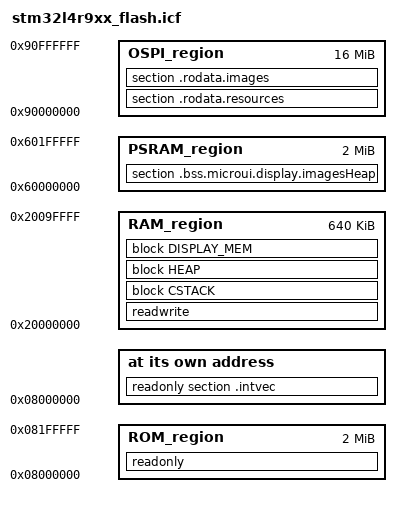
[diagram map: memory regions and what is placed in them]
/*
 * Copyright 2019-2022 MicroEJ Corp. All rights reserved.
 * Use of this source code is governed by a BSD-style license that can be found with this software.
 */

/*-Specials-*/
define symbol __ICFEDIT_intvec_start__ = 0x08000000;
/*-Memory Regions-*/
define symbol __ICFEDIT_region_ROM_start__    = 0x08000000;
define symbol __ICFEDIT_region_ROM_end__      = 0x081FFFFF;
define symbol __ICFEDIT_region_RAM_start__    = 0x20000000;
define symbol __ICFEDIT_region_RAM_end__      = 0x2009FFFF;
define symbol __ICFEDIT_region_PSRAM_start__  = 0x60000000;
define symbol __ICFEDIT_region_PSRAM_end__    = 0x601FFFFF;
define symbol __ICFEDIT_region_OSPI_start__   = 0x90000000;
define symbol __ICFEDIT_region_OSPI_end__     = 0x90FFFFFF;

/*-Sizes-*/
define symbol __ICFEDIT_size_cstack__ = 0x400;
define symbol __ICFEDIT_size_heap__   = 0x200;
/*define symbol __ICFEDIT_size_lcdbuffer__  = 0x3B6A0; /* (390*390*16/8)x80% (GFXMMU) */
/*define symbol __ICFEDIT_size_lcdbuffer__  = 0x591F0; /* (390*390*24/8)x80% (GFXMMU) */
/*define symbol __ICFEDIT_size_lcdbuffer__  = 0x76D40; /* (390*390*32/8)x80% (GFXMMU) */
/*define symbol __ICFEDIT_size_lcdbuffer__  = 0x6F66C; /* 24 BPP, no GFXMMU */
define symbol __ICFEDIT_size_lcdbuffer__  = 0x4A448; /* 16 BPP, no GFXMMU 
/**** End of ICF editor section. ###ICF###*/


define memory mem with size = 4G;
define region ROM_region      = mem:[from __ICFEDIT_region_ROM_start__   to __ICFEDIT_region_ROM_end__];
define region RAM_region      = mem:[from __ICFEDIT_region_RAM_start__   to __ICFEDIT_region_RAM_end__];
define region PSRAM_region    = mem:[from __ICFEDIT_region_PSRAM_start__ to __ICFEDIT_region_PSRAM_end__];
define region OSPI_region     = mem:[from __ICFEDIT_region_OSPI_start__  to __ICFEDIT_region_OSPI_end__];

define block CSTACK    with alignment = 8, size = __ICFEDIT_size_cstack__   { };
define block HEAP      with alignment = 8, size = __ICFEDIT_size_heap__     { };
define block DISPLAY_MEM      with alignment = 16, size = __ICFEDIT_size_lcdbuffer__     { };

initialize by copy { readwrite };
do not initialize  { section .noinit };

place at address mem:__ICFEDIT_intvec_start__ { readonly section .intvec };

place in ROM_region   { readonly };
place in RAM_region   { readwrite,
                        block CSTACK, block HEAP, block DISPLAY_MEM };
place in PSRAM_region   {section .bss.microui.display.imagesHeap };
place in OSPI_region   {section .rodata.resources, section .rodata.images };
